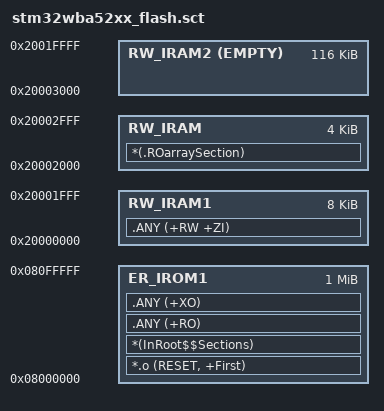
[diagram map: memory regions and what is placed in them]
; *************************************************************
; *** Scatter-Loading Description File generated by uVision ***
; *************************************************************

LR_IROM1 0x08000000 0x00100000  {    ; load region size_region
  ER_IROM1 0x08000000 0x00100000  {  ; load address = execution address
   *.o (RESET, +First)
   *(InRoot$$Sections)
   .ANY (+RO)
   .ANY (+XO)
  }
  RW_IRAM1 0x20000000 0x0002000  {  ; RW data
   .ANY (+RW +ZI)
  }
    RW_IRAM  0x20002000 0x00001000 {
  *(.ROarraySection)
  }
  ; Backup SRAM2
  RW_IRAM2 0x20003000 EMPTY 0x0001D000  {  ; to be modified accordingly to user project. Can be NoInit data for backup usage, RW, ZI region, etc...
  }
}

